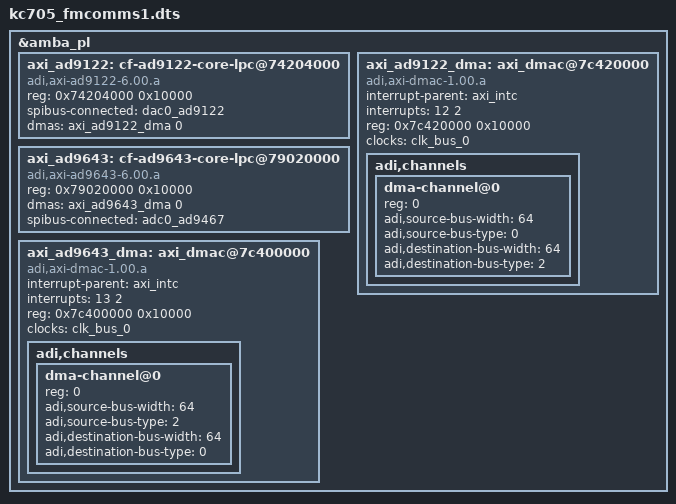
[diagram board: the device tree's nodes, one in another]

/dts-v1/;
#include "kc705.dtsi"

#define fmc_i2c fmc_lpc_iic

&amba_pl {
	axi_ad9122: cf-ad9122-core-lpc@74204000 {
		compatible = "adi,axi-ad9122-6.00.a";
		reg = <0x74204000 0x10000>;
		spibus-connected = <&dac0_ad9122>;
		dmas = <&axi_ad9122_dma 0>;
		dma-names = "tx";
	};
	axi_ad9122_dma: axi_dmac@7c420000 {
		compatible = "adi,axi-dmac-1.00.a";
		interrupt-parent = <&axi_intc>;
		interrupts = <12 2>;
		reg = <0x7c420000 0x10000>;
		#dma-cells = <1>;
		clocks = <&clk_bus_0>;

		adi,channels {
			#size-cells = <0>;
			#address-cells = <1>;

			dma-channel@0 {
				reg = <0>;
				adi,source-bus-width = <64>;
				adi,source-bus-type = <0>;
				adi,destination-bus-width = <64>;
				adi,destination-bus-type = <2>;
			};
		};
	};
	axi_ad9643: cf-ad9643-core-lpc@79020000 {
		compatible = "adi,axi-ad9643-6.00.a";
		reg = <0x79020000 0x10000>;
		dmas = <&axi_ad9643_dma 0>;
		dma-names = "rx";
		spibus-connected = <&adc0_ad9467>;
	};
	axi_ad9643_dma: axi_dmac@7c400000 {
		compatible = "adi,axi-dmac-1.00.a";
		interrupt-parent = <&axi_intc>;
		interrupts = <13 2>;
		reg = <0x7c400000 0x10000>;
		#dma-cells = <1>;
		clocks = <&clk_bus_0>;

		adi,channels {
			#size-cells = <0>;
			#address-cells = <1>;

			dma-channel@0 {
				reg = <0>;
				adi,source-bus-width = <64>;
				adi,source-bus-type = <2>;
				adi,destination-bus-width = <64>;
				adi,destination-bus-type = <0>;
			};
		};
	};
};

#include "adi-fmcomms1.dtsi"
